# iostr731 register map
Registers are 16-bit, access not given, no defined reset value unless marked. A register's access mark holds for its fields unless they carry their own. Addresses are absolute; registers are grouped by the start of their names; [hi:lo] are bit positions; {n}, {i} and the like mark numbered series.

## PWM0
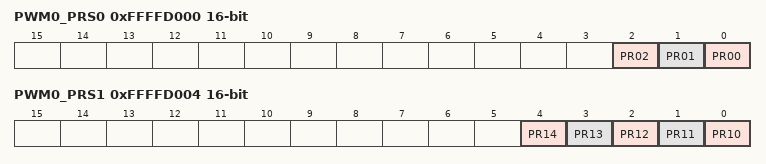
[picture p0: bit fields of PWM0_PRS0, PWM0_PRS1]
0xFFFFD000 PWM0_PRS0
  [2] PR02, [1] PR01, [0] PR00
0xFFFFD004 PWM0_PRS1
  [n-10] PR{n} (n=10..14)
0xFFFFD008 PWM0_PEN
  [0] PE
0xFFFFD00C PWM0_PLS
  [0] PL
0xFFFFD010 PWM0_CPI
  [0] CP
0xFFFFD014 PWM0_IM
  [0] IM
0xFFFFD01C PWM0_DUT
0xFFFFD020 PWM0_PER

## PWM1
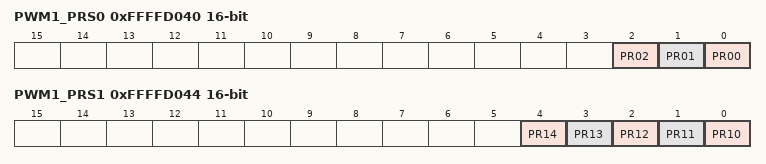
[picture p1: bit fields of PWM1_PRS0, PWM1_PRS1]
0xFFFFD040 PWM1_PRS0
  [2] PR02, [1] PR01, [0] PR00
0xFFFFD044 PWM1_PRS1
  [n-10] PR{n} (n=10..14)
0xFFFFD048 PWM1_PEN
  [0] PE
0xFFFFD04C PWM1_PLS
  [0] PL
0xFFFFD050 PWM1_CPI
  [0] CP
0xFFFFD054 PWM1_IM
  [0] IM
0xFFFFD05C PWM1_DUT
0xFFFFD060 PWM1_PER

## PWM2
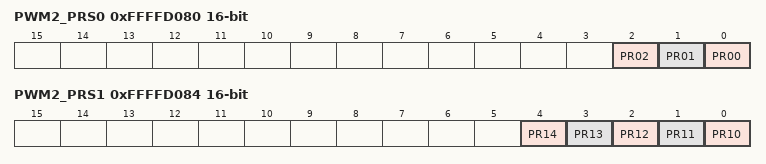
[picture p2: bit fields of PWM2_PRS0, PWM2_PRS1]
0xFFFFD080 PWM2_PRS0
  [2] PR02, [1] PR01, [0] PR00
0xFFFFD084 PWM2_PRS1
  [n-10] PR{n} (n=10..14)
0xFFFFD088 PWM2_PEN
  [0] PE
0xFFFFD08C PWM2_PLS
  [0] PL
0xFFFFD090 PWM2_CPI
  [0] CP
0xFFFFD094 PWM2_IM
  [0] IM
0xFFFFD09C PWM2_DUT
0xFFFFD0A0 PWM2_PER

## PWM3
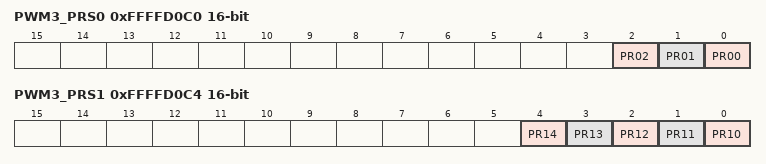
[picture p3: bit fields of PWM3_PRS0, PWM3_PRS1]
0xFFFFD0C0 PWM3_PRS0
  [2] PR02, [1] PR01, [0] PR00
0xFFFFD0C4 PWM3_PRS1
  [n-10] PR{n} (n=10..14)
0xFFFFD0C8 PWM3_PEN
  [0] PE
0xFFFFD0CC PWM3_PLS
  [0] PL
0xFFFFD0D0 PWM3_CPI
  [0] CP
0xFFFFD0D4 PWM3_IM
  [0] IM
0xFFFFD0DC PWM3_DUT
0xFFFFD0E0 PWM3_PER

## PWM4
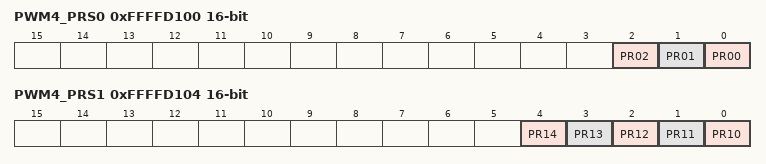
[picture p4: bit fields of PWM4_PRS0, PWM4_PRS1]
0xFFFFD100 PWM4_PRS0
  [2] PR02, [1] PR01, [0] PR00
0xFFFFD104 PWM4_PRS1
  [n-10] PR{n} (n=10..14)
0xFFFFD108 PWM4_PEN
  [0] PE
0xFFFFD10C PWM4_PLS
  [0] PL
0xFFFFD110 PWM4_CPI
  [0] CP
0xFFFFD114 PWM4_IM
  [0] IM
0xFFFFD11C PWM4_DUT
0xFFFFD120 PWM4_PER

## PWM5
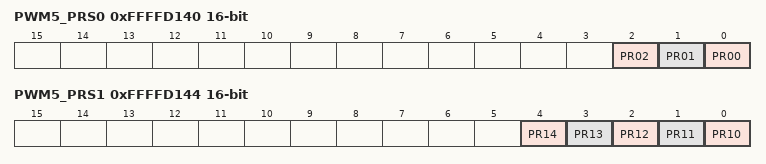
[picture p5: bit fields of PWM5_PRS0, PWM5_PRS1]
0xFFFFD140 PWM5_PRS0
  [2] PR02, [1] PR01, [0] PR00
0xFFFFD144 PWM5_PRS1
  [n-10] PR{n} (n=10..14)
0xFFFFD148 PWM5_PEN
  [0] PE
0xFFFFD14C PWM5_PLS
  [0] PL
0xFFFFD150 PWM5_CPI
  [0] CP
0xFFFFD154 PWM5_IM
  [0] IM
0xFFFFD15C PWM5_DUT
0xFFFFD160 PWM5_PER

## GPIOPORT0
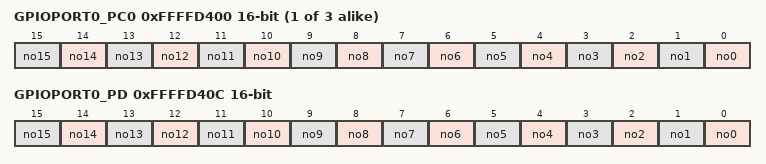
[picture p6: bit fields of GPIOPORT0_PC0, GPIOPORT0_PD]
{0xFFFFD400+4i} GPIOPORT0_PC{i} (i=0..2)
  [n] no{n} (n=0..15)
0xFFFFD40C GPIOPORT0_PD
  [n] no{n} (n=0..15)

## GPIOPORT1
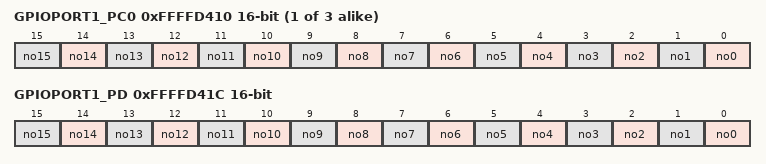
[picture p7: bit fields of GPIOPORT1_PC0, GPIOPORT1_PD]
{0xFFFFD410+4i} GPIOPORT1_PC{i} (i=0..2)
  [n] no{n} (n=0..15)
0xFFFFD41C GPIOPORT1_PD
  [n] no{n} (n=0..15)

## GPIOPORT2
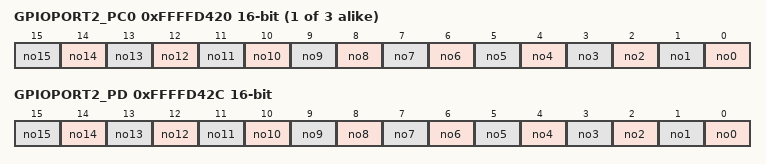
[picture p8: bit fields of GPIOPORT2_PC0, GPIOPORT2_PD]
{0xFFFFD420+4i} GPIOPORT2_PC{i} (i=0..2)
  [n] no{n} (n=0..15)
0xFFFFD42C GPIOPORT2_PD
  [n] no{n} (n=0..15)

## GPIOPORT3
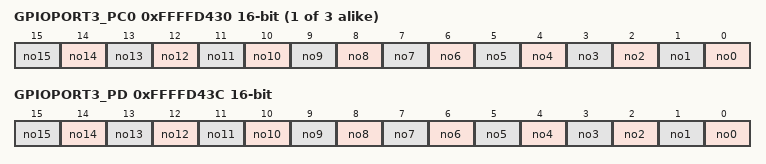
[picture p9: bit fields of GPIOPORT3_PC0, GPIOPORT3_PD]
{0xFFFFD430+4i} GPIOPORT3_PC{i} (i=0..2)
  [n] no{n} (n=0..15)
0xFFFFD43C GPIOPORT3_PD
  [n] no{n} (n=0..15)

## GPIOPORT4
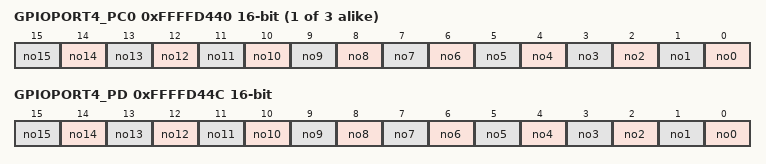
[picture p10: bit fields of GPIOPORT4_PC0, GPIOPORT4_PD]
{0xFFFFD440+4i} GPIOPORT4_PC{i} (i=0..2)
  [n] no{n} (n=0..15)
0xFFFFD44C GPIOPORT4_PD
  [n] no{n} (n=0..15)

## GPIOPORT5
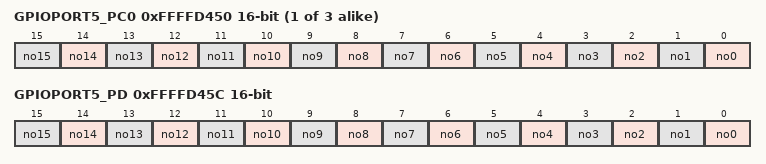
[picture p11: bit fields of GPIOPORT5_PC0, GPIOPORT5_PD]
{0xFFFFD450+4i} GPIOPORT5_PC{i} (i=0..2)
  [n] no{n} (n=0..15)
0xFFFFD45C GPIOPORT5_PD
  [n] no{n} (n=0..15)

## GPIOPORT6
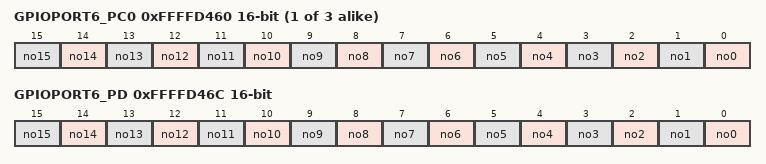
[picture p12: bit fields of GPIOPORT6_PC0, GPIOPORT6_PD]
{0xFFFFD460+4i} GPIOPORT6_PC{i} (i=0..2)
  [n] no{n} (n=0..15)
0xFFFFD46C GPIOPORT6_PD
  [n] no{n} (n=0..15)

## BSPI0
0xFFFFD800 BSPI0_RXR
0xFFFFD804 BSPI0_TXR
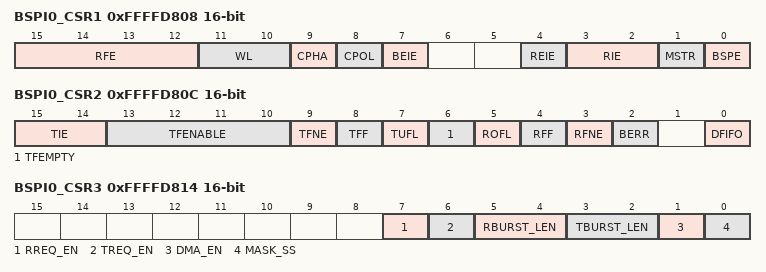
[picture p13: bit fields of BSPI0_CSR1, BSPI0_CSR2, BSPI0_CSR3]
0xFFFFD808 BSPI0_CSR1
  [15:12] RFE, [11:10] WL, [9] CPHA, [8] CPOL, [7] BEIE, [4] REIE, [3:2] RIE, [1] MSTR, [0] BSPE
0xFFFFD80C BSPI0_CSR2
  [15:14] TIE, [13:10] TFENABLE, [9] TFNE, [8] TFF, [7] TUFL, [6] TFEMPTY, [5] ROFL, [4] RFF, [3] RFNE, [2] BERR, [0] DFIFO
0xFFFFD810 BSPI0_CLK
  [7:0] DIV
0xFFFFD814 BSPI0_CSR3
  [7] RREQ_EN, [6] TREQ_EN, [5:4] RBURST_LEN, [3:2] TBURST_LEN, [1] DMA_EN, [0] MASK_SS

## BSPI1
0xFFFFDC00 BSPI1_RXR
0xFFFFDC04 BSPI1_TXR
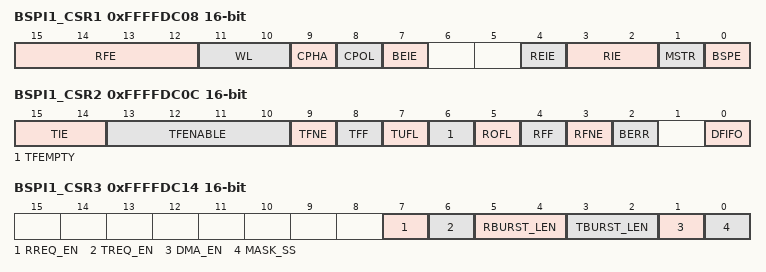
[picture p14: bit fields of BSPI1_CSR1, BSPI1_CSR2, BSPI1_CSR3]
0xFFFFDC08 BSPI1_CSR1
  [15:12] RFE, [11:10] WL, [9] CPHA, [8] CPOL, [7] BEIE, [4] REIE, [3:2] RIE, [1] MSTR, [0] BSPE
0xFFFFDC0C BSPI1_CSR2
  [15:14] TIE, [13:10] TFENABLE, [9] TFNE, [8] TFF, [7] TUFL, [6] TFEMPTY, [5] ROFL, [4] RFF, [3] RFNE, [2] BERR, [0] DFIFO
0xFFFFDC10 BSPI1_CLK
  [7:0] DIV
0xFFFFDC14 BSPI1_CSR3
  [7] RREQ_EN, [6] TREQ_EN, [5:4] RBURST_LEN, [3:2] TBURST_LEN, [1] DMA_EN, [0] MASK_SS
